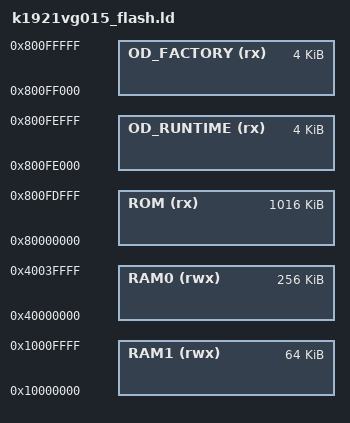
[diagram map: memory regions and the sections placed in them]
/** @file
*  @brief linker script for K1921VG015
*/

OUTPUT_ARCH( "riscv" )
ENTRY(_start)

MEMORY {
  ROM  (rx)  : ORIGIN = 0x80000000, LENGTH = 1024K - 8K
  OD_RUNTIME (rx) : ORIGIN = 0x80000000 + 1016K, LENGTH = 4K
  OD_FACTORY (rx) : ORIGIN = 0x80000000 + 1020K, LENGTH = 4K
  RAM0 (rwx) : ORIGIN = 0x40000000, LENGTH = 256K
  RAM1 (rwx) : ORIGIN = 0x10000000, LENGTH = 64K
}

REGION_ALIAS("REGION_TEXT",   ROM );
REGION_ALIAS("REGION_RODATA", ROM );
REGION_ALIAS("REGION_DATA",   RAM0);
REGION_ALIAS("REGION_BSS",    RAM0);
REGION_ALIAS("REGION_STACK",  RAM0);

STACK_SIZE = 4096;
HEAP_SIZE  = 32768;

INCLUDE "k1921vg015_common.lds"
